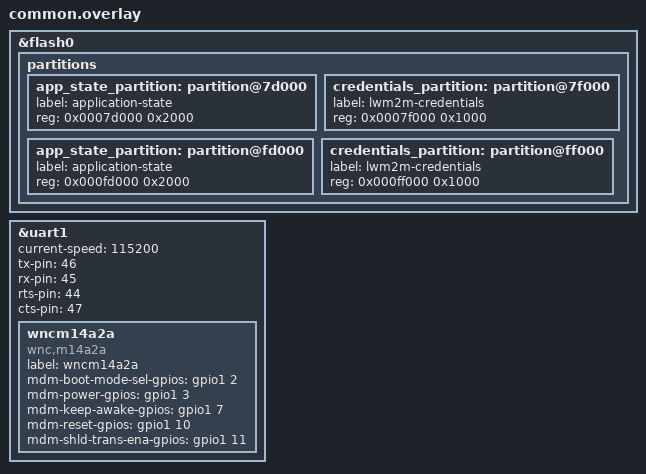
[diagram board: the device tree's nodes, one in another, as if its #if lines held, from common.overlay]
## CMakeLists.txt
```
cmake_minimum_required(VERSION 3.8.2)

# This application has its own Kconfig options.
set(KCONFIG_ROOT ${CMAKE_CURRENT_SOURCE_DIR}/Kconfig)

# CONF_FILE is prj.conf, plus (in addition to, not or) the following, if they
# exist:
#   - local.conf
#   - boards/${BOARD}.conf
#   - boards/${BOARD}-local.conf
#
# The possibly nonexistent files need to be absolute paths; otherwise, the
# behavior of EXISTS is not well-defined.
set(CONF_FILE prj.conf)
if(EXISTS ${CMAKE_CURRENT_SOURCE_DIR}/local.conf)
  set(CONF_FILE ${CONF_FILE} " local.conf")
endif()
if(EXISTS ${CMAKE_CURRENT_SOURCE_DIR}/boards/${BOARD}.conf)
  set(CONF_FILE ${CONF_FILE} " boards/${BOARD}.conf")
endif()
if(EXISTS ${CMAKE_CURRENT_SOURCE_DIR}/boards/${BOARD}-local.conf)
  set(CONF_FILE ${CONF_FILE} " boards/${BOARD}-local.conf")
endif()

if(EXISTS ${CMAKE_CURRENT_SOURCE_DIR}/boards/${BOARD}.overlay)
  # Individual boards must provide DTS overlays which declare the
  # application state partition, and, as appropriate, the DTLS
  # partition.
  set(DTC_OVERLAY_FILE ${DTC_OVERLAY_FILE} " ${CMAKE_CURRENT_SOURCE_DIR}/boards/${BOARD}.overlay")
else()
  # We used to be able to try to go on based on SoC-level defaults,
  # but now that DTS runs before Kconfig, we can't ifdef on the SoC in
  # a DTS overlay anymore. Absent a better solution, fail.
  message(FATAL_ERROR
    "Missing board support for this application; please write
    ${CMAKE_CURRENT_SOURCE_DIR}/boards/${BOARD}.overlay. (This is
    needed for now because DTS now runs before KConfig, so SoC-level
    defaults cannot be applied.)")
endif()

# Mandatory Zephyr boilerplate.
include($ENV{ZEPHYR_BASE}/cmake/app/boilerplate.cmake NO_POLICY_SCOPE)
project(NONE)

# Application "library" build configuration. TODO: move these out of this tree.
target_sources(app PRIVATE src/lib/product_id.c)
target_sources(app PRIVATE src/lib/lwm2m_credentials.c)

# Application build configuration.
target_include_directories(app PRIVATE $ENV{ZEPHYR_BASE}/subsys/testsuite/include/)
target_include_directories(app PRIVATE ${CMAKE_CURRENT_SOURCE_DIR}/src/lib)

target_sources(app PRIVATE src/main.c)
target_sources(app PRIVATE src/app_work_queue.c)
target_sources(app PRIVATE src/lwm2m.c)
target_sources(app PRIVATE src/settings.c)
target_sources(app PRIVATE src/light_control.c)
target_sources_ifdef(CONFIG_NET_L2_BT        app PRIVATE src/bluetooth.c)

target_link_libraries_ifdef(CONFIG_MBEDTLS app PRIVATE mbedTLS)
```

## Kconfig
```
# Copyright (c) 2017 Linaro Limited
# Copyright (c) 2018 Foundries.io
#
# SPDX-License-Identifier: Apache-2.0
#

mainmenu "LWM2M application configuration"

choice
	prompt "FOTA network interface"
	default FOTA_NET_OPENTHREAD if SOC_NRF52840
	default FOTA_NET_BLE6LOWPAN if SOC_NRF52832
	default FOTA_NET_DEFAULT
	help
	  This selection represents an abstract choice for network interface
	  which in turn allows us to set the HW specific configs.

config FOTA_NET_OPENTHREAD
	bool "OpenThread"
	help
	  Connect to host via OpenThread

config FOTA_NET_802154
	bool "IEEE 802.15.4"
	help
	  Connect to host via IEEE 802.15.4

config FOTA_NET_BLE6LOWPAN
	bool "BLE 6LoWPAN"
	help
	  Connect to host via BLE / 6LoWPAN

config FOTA_NET_MODEM
	bool "Modem"
	help
	  Connect to host via modem

config FOTA_NET_DEFAULT
	bool "Other"
	help
	  Connect to host via HW default method (ethernet, etc)

endchoice

config FOTA_DEVICE
	bool "Enable FOTA device settings"
	default y
	select FOTA_DEVICE_SOC_SERIES_KINETIS_K6X if SOC_SERIES_KINETIS_K6X
	select FOTA_DEVICE_SOC_SERIES_NRF52X if SOC_SERIES_NRF52X
	select NET_IPV6 if FOTA_NET_OPENTHREAD || FOTA_NET_BLE6LOWPAN || FOTA_NET_802154
	select NET_CONFIG_NEED_IPV6 if FOTA_NET_OPENTHREAD || FOTA_NET_BLE6LOWPAN || FOTA_NET_802154
	select NET_IPV4 if FOTA_NET_MODEM
	select NET_CONFIG_NEED_IPV4 if FOTA_NET_MODEM
	help
	  Main config to enable device specific settings

config FOTA_ENDPOINT_PREFIX
	string "LwM2M endpoint will start with this string"
	default "zmp"
	help
	  LwM2M endpoint names follow this format "<prefix>:sn:<serial #>".
	  This setting allows you to set the "zmp" portion to a custom value.

config FOTA_DEVICE_SOC_SERIES_KINETIS_K6X
	bool "Kinetis K6x FOTA settings"
	select NET_SHELL
	select NET_IPV4
	select NET_UDP
	select NET_CONFIG_NEED_IPV4
	select NET_DHCPV4 if !FOTA_NET_MODEM
	default n

if FOTA_DEVICE_SOC_SERIES_KINETIS_K6X

# IPv6 is enabled by default in Zephyr's Kconfig when networking is selected.
config NET_IPV6
	default n
config NET_CONFIG_NEED_IPV6
	default n

endif # FOTA_DEVICE_SOC_SERIES_KINETIS_K6X

config FOTA_DEVICE_SOC_SERIES_NRF52X
	bool "Nordic Semiconductor nRF52 FOTA settings"
	select SENSOR
	select TEMP_NRF5
	select ENTROPY_NRF5_RNG
	select NET_SHELL if SOC_NRF52840
	default n

config FOTA_LED_GPIO_INVERTED
	bool "Set this if your hardware has an inverted LED GPIO"
	default y if SOC_NRF52840
	help
	  This setting is used to invert the GPIO pin settings when toggling
	  the "Light Control" LED.

config FOTA_ERASE_PROGRESSIVELY
	bool "Erase flash progressively when updating/receiving new firmware"
	default y if SOC_NRF52840
	help
	 If enabled, flash is erased as necessary when receiving and marking
         new firmware as ok, instead of erasing the whole image slot at once.
         This is necessary on some hardware that has long erase times, to
         prevent long wait times at various stages where large erases are
         performed.

if FOTA_DEVICE_SOC_SERIES_NRF52X

config TEMP_NRF5_NAME
	default "fota-temp"

endif # FOTA_DEVICE_SOC_SERIES_NRF52X

# OpenThread settings
if FOTA_NET_OPENTHREAD
rsource "network_defaults/Kconfig.defaults.ot"
endif # FOTA_NET_OPENTHREAD

# IEEE 802.15.4 Settings
if FOTA_NET_802154
rsource "network_defaults/Kconfig.defaults.ieee802154"
endif # FOTA_NET_802154

# BLE / 6LoWPAN settings
if FOTA_NET_BLE6LOWPAN
rsource "network_defaults/Kconfig.defaults.ble6lowpan"
endif # FOTA_NET_BLE6LOWPAN

# Modem Settings
if FOTA_NET_MODEM
rsource "network_defaults/Kconfig.defaults.modem"
endif # FOTA_NET_MODEM

# General defaults

config NET_RX_STACK_SIZE
	default 5120 if FOTA_NET_OPENTHREAD
	default 2048

config DNS_SERVER1
	default "8.8.8.8" if FOTA_NET_MODEM || FOTA_NET_DEFAULT

module = FOTA
module-dep = LOG
module-str = Log level for FOTA application
source "subsys/logging/Kconfig.template.log_config"

# Leave this at the bottom: we need to override Zephyr's default settings
# with some of the values above.
source "$ZEPHYR_BASE/Kconfig.zephyr"
```

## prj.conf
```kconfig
CONFIG_BOOT_BANNER=y
CONFIG_REBOOT=y
CONFIG_FLASH=y
CONFIG_FLASH_PAGE_LAYOUT=y
CONFIG_NETWORKING=y
CONFIG_GPIO=y

# Network
CONFIG_NET_UDP=y
CONFIG_NET_MGMT=y
CONFIG_NET_MGMT_EVENT=y
CONFIG_NET_PKT_RX_COUNT=10
CONFIG_NET_PKT_TX_COUNT=10
CONFIG_NET_BUF_RX_COUNT=10
CONFIG_NET_BUF_TX_COUNT=10

# FOTA
CONFIG_BOOTLOADER_MCUBOOT=y
CONFIG_FOTA_DEVICE=y
CONFIG_IMG_MANAGER=y
CONFIG_MCUBOOT_IMG_MANAGER=y
# Enable settings storage
CONFIG_SETTINGS=y
CONFIG_FCB=y
CONFIG_SETTINGS_FCB=y

# CONFIG
CONFIG_NET_CONFIG_SETTINGS=y
CONFIG_NET_CONFIG_PEER_IPV6_ADDR="mgmt.foundries.io"
CONFIG_NET_CONFIG_PEER_IPV4_ADDR="mgmt.foundries.io"

# LWM2M
CONFIG_LWM2M=y
CONFIG_LWM2M_SERVER_INSTANCE_COUNT=2
# CONFIG_LWM2M_RW_JSON_SUPPORT is not set
CONFIG_LWM2M_COAP_BLOCK_SIZE=256
CONFIG_LWM2M_IPSO_SUPPORT=y
CONFIG_LWM2M_IPSO_TEMP_SENSOR=y
CONFIG_LWM2M_IPSO_LIGHT_CONTROL=y

# Extra COAP settings
CONFIG_COAP_EXTENDED_OPTIONS_LEN=y
CONFIG_COAP_EXTENDED_OPTIONS_LEN_VALUE=32

# Logging
CONFIG_LOG=y
CONFIG_LOG_DEFAULT_LEVEL=0
CONFIG_BT_LOG_LEVEL_OFF=y
CONFIG_FOTA_LOG_LEVEL_DBG=y
CONFIG_LWM2M_LOG_LEVEL_INF=y

# DNS
CONFIG_DNS_RESOLVER=y
CONFIG_DNS_SERVER_IP_ADDRESSES=y
# Set DNS server entries Kconfig and boards/*.conf
# Needed by socket-based DNS lookup
CONFIG_MINIMAL_LIBC_MALLOC_ARENA_SIZE=360

# Bluetooth (when enabled) debug
#CONFIG_BT_DEBUG_LOG=y
#CONFIG_BT_DEBUG_HCI_DRIVER=y

# Add flash RW to MPU
CONFIG_MPU_ALLOW_FLASH_WRITE=y

# LwM2M workqueue requires a larger stack
CONFIG_SYSTEM_WORKQUEUE_STACK_SIZE=2048

# Debug helpers
#CONFIG_NET_LOG=y
#CONFIG_NET_SOCKETS_LOG_LEVEL_DBG=y
#CONFIG_NET_CORE_LOG_LEVEL_DBG=y
#CONFIG_NET_IF_LOG_LEVEL_DBG=y
#CONFIG_NET_UTILS_LOG_LEVEL_DBG=y
#CONFIG_NET_CONTEXT_LOG_LEVEL_DBG=y
#CONFIG_NET_PKT_LOG_LEVEL_DBG=y
#CONFIG_NET_DEBUG_NET_PKT_ALLOC=y
#CONFIG_NET_BUF_POOL_USAGE=y
#CONFIG_NET_CONN_LOG_LEVEL_DBG=y
#CONFIG_NET_ROUTE_LOG_LEVEL_DBG=y
#CONFIG_NET_IPV4_LOG_LEVEL_DBG=y
#CONFIG_NET_IPV6_LOG_LEVEL_DBG=y
#CONFIG_NET_ICMPV6_LOG_LEVEL_DBG=y
#CONFIG_NET_IPV6_NBR_CACHE_LOG_LEVEL_DBG=y
#CONFIG_NET_6LO_LOG_LEVEL_DBG=y
#CONFIG_NET_UDP_LOG_LEVEL_DBG=y
#CONFIG_NET_L2_ETHERNET_LOG_LEVEL_DBG=y
#CONFIG_NET_L2_BT_LOG_LEVEL_DBG=y
#CONFIG_MODEM_LOG_LEVEL_DBG=y
#CONFIG_INIT_STACKS=y
#CONFIG_STACK_USAGE=y
#CONFIG_STACK_SENTINEL=y
```

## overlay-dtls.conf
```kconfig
CONFIG_LWM2M_DTLS_SUPPORT=y
CONFIG_LWM2M_PEER_PORT=5684

# Special MbedTLS changes
CONFIG_MBEDTLS_HEAP_SIZE=8192
CONFIG_MBEDTLS_SSL_MAX_CONTENT_LEN=1500
CONFIG_MBEDTLS_CIPHER_CCM_ENABLED=y

# Disable RSA, we don't parse certs: saves flash/memory
CONFIG_MBEDTLS_KEY_EXCHANGE_RSA_ENABLED=n
# Enable PSK instead
CONFIG_MBEDTLS_KEY_EXCHANGE_PSK_ENABLED=y

CONFIG_NET_SOCKETS_SOCKOPT_TLS=y
CONFIG_NET_SOCKETS_TLS_MAX_CONTEXTS=4
CONFIG_NET_SOCKETS_ENABLE_DTLS=y

# MbedTLS needs a larger stack
CONFIG_MAIN_STACK_SIZE=2048

# Decrease log level to fit inside flash space
CONFIG_FOTA_LOG_LEVEL_INF=y

# This defaults to y in our configuration, but we aren't relying on
# link layer security and it puts us over our flash budget, so turn it
# back off for now.
# CONFIG_BT_TINYCRYPT_ECC is not set
```

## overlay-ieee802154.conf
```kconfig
# Disable BT configs enabled via board/* conf files
CONFIG_BT=n
CONFIG_BT_CTLR=n
CONFIG_NET_L2_BT=n

# Enable IEEE80215 configs
CONFIG_IEEE802154=y
CONFIG_NET_L2_IEEE802154=y
CONFIG_NET_L2_IEEE802154_SHELL=y
```

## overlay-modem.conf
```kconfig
# Enable WNC-M14A2A LTE-M Modem
CONFIG_MODEM=y
CONFIG_MODEM_SHELL=y
CONFIG_MODEM_WNCM14A2A=y

# extend retry timing to 20 seconds for LTE/LTE-M
CONFIG_COAP_INIT_ACK_TIMEOUT_MS=20000

# Enable modem log
CONFIG_MODEM_LOG_LEVEL_DBG=y
```

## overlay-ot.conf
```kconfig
# Hack: Disable BT on devices which support both for now
CONFIG_BT=n

# Enable OpenThread
CONFIG_NET_L2_OPENTHREAD=y

# Enable C++ for OpenThread stack compilation
CONFIG_CPLUSPLUS=y

# Enable flash page layout extension
CONFIG_FLASH_PAGE_LAYOUT=y

# OpenThread doesn't use NS/NA
CONFIG_NET_IPV6_NBR_CACHE=n
CONFIG_NET_IPV6_MLD=n

# OpenThread requires larger stack sizes
CONFIG_MAIN_STACK_SIZE=2048
CONFIG_SYSTEM_WORKQUEUE_STACK_SIZE=2048
CONFIG_NET_TX_STACK_SIZE=2048

# Use CoAP proxy on gateway
CONFIG_LWM2M_FIRMWARE_UPDATE_PULL_COAP_PROXY_SUPPORT=y
CONFIG_LWM2M_FIRMWARE_UPDATE_PULL_COAP_PROXY_ADDR="coap://[fd11:22::1]:5682"

# Use DNS64 on gateway
CONFIG_DNS_SERVER1="fd11:22::1"

CONFIG_NET_CONFIG_INIT_TIMEOUT=90
```

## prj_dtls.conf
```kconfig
CONFIG_BOOT_BANNER=y
CONFIG_BUILD_TIMESTAMP=y
CONFIG_REBOOT=y
CONFIG_FLASH=y
CONFIG_NETWORKING=y

# Leave device specific settings to enable IPV*
CONFIG_NET_IPV6=n
CONFIG_NET_IPV4=n

# Network
CONFIG_NET_UDP=y
CONFIG_NET_MGMT=y
CONFIG_NET_MGMT_EVENT=y
CONFIG_NET_RX_STACK_SIZE=2048
CONFIG_NET_PKT_RX_COUNT=10
CONFIG_NET_PKT_TX_COUNT=10
CONFIG_NET_BUF_RX_COUNT=10
CONFIG_NET_BUF_TX_COUNT=10

# FOTA
CONFIG_BOOTLOADER_MCUBOOT=y
CONFIG_FOTA_DEVICE=y
CONFIG_IMG_MANAGER=y
CONFIG_MCUBOOT_IMG_MANAGER=y

# NET APP
CONFIG_NET_APP=y
CONFIG_NET_APP_NEED_IPV6=n
CONFIG_NET_APP_NEED_IPV4=n
CONFIG_NET_APP_CLIENT=y
CONFIG_NET_APP_SETTINGS=y
CONFIG_NET_APP_BT_NODE=y
CONFIG_BT_DEVICE_NAME="Linaro IPSP node"
# following BT-related configs which are not needed as a peripheral
CONFIG_BT_CTLR_CONN_PARAM_REQ=n
CONFIG_BT_CTLR_ADV_EXT=n

# COAP
CONFIG_COAP_EXTENDED_OPTIONS_LEN=y
CONFIG_COAP_EXTENDED_OPTIONS_LEN_VALUE=32

# LWM2M
CONFIG_LWM2M=y
CONFIG_LWM2M_RD_CLIENT_INSTANCE_COUNT=1
CONFIG_LWM2M_ENGINE_MAX_OBSERVER=10
CONFIG_LWM2M_SERVER_INSTANCE_COUNT=2
# CONFIG_LWM2M_RW_JSON_SUPPORT is not set
CONFIG_LWM2M_COAP_BLOCK_SIZE=256
CONFIG_LWM2M_FIRMWARE_UPDATE_PULL_COAP_PROXY_SUPPORT=y
CONFIG_LWM2M_IPSO_SUPPORT=y
CONFIG_LWM2M_IPSO_TEMP_SENSOR=y
CONFIG_LWM2M_IPSO_LIGHT_CONTROL=y
CONFIG_SYS_LOG_LWM2M_LEVEL=3

# Logging
CONFIG_SYS_LOG=y
# HACK: temporarily make room on flash
# CONFIG_SYS_LOG_EXT_HOOK is not set
CONFIG_SYS_LOG_FOTA_LEVEL=3

# Bluetooth (when enabled) debug
#CONFIG_BT_DEBUG_LOG=y
#CONFIG_BT_DEBUG_HCI_DRIVER=y

# Add flash RW to MPU
CONFIG_MPU_ALLOW_FLASH_WRITE=y

# DTLS settings
CONFIG_NET_APP_DTLS=y
CONFIG_MBEDTLS=y
CONFIG_MBEDTLS_BUILTIN=y
CONFIG_MBEDTLS_ENABLE_HEAP=y
CONFIG_MBEDTLS_HEAP_SIZE=8192
CONFIG_MBEDTLS_CFG_FILE="config-coap.h"
CONFIG_LWM2M_PEER_PORT=5684

# Debug helpers
#CONFIG_NET_LOG=y
#CONFIG_SYS_LOG_NET_LEVEL=4
#CONFIG_NET_DEBUG_CORE=y
#CONFIG_NET_DEBUG_APP=y
#CONFIG_NET_DEBUG_IF=y
#CONFIG_NET_DEBUG_UTILS=y
#CONFIG_NET_DEBUG_CONTEXT=y
#CONFIG_NET_DEBUG_NET_PKT=y
#CONFIG_NET_DEBUG_NET_PKT_ALL=y
#CONFIG_NET_DEBUG_CONN=y
#CONFIG_NET_DEBUG_ROUTE=y
#CONFIG_NET_DEBUG_IPV4=y
#CONFIG_NET_DEBUG_IPV6=y
#CONFIG_NET_DEBUG_ICMPV6=y
#CONFIG_NET_DEBUG_IPV6_NBR_CACHE=y
#CONFIG_NET_DEBUG_6LO=y
#CONFIG_NET_DEBUG_UDP=y
#CONFIG_NET_DEBUG_L2_ETHERNET=y
#CONFIG_NET_DEBUG_L2_BT=y
#CONFIG_INIT_STACKS=y
#CONFIG_STACK_USAGE=y
```

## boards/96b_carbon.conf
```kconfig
# network stack settings
CONFIG_NET_IF_UNICAST_IPV6_ADDR_COUNT=3
CONFIG_NET_IF_MCAST_IPV6_ADDR_COUNT=2

# bluetooth settings
CONFIG_BLUETOOTH_RX_BUF_COUNT=10
CONFIG_BLUETOOTH_RX_BUF_LEN=128
CONFIG_BLUETOOTH_CONTROLLER_RX_BUFFERS=6
CONFIG_BLUETOOTH_CONTROLLER_TX_BUFFERS=7
CONFIG_BLUETOOTH_RX_STACK_SIZE=2048

# HW settings
CONFIG_TEXT_SECTION_OFFSET=0x100

# temp settings
CONFIG_TEMP_STM32F401X_NAME="fota-mcu-temp"

# Default IP configuration for IPv6 (gateway)
CONFIG_NET_APP_PEER_IPV6_ADDR="fe80::d4e7:0:0:1"

# LWM2M (gateway)
CONFIG_LWM2M_FIRMWARE_UPDATE_PULL_COAP_PROXY_ADDR="fe80::d4e7:0:0:1"
```

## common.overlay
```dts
/*
 * DT overlay file for nodes shared across multiple boards
 * that is *not* shared with the MCUboot build.
 */

#ifdef CONFIG_SOC_NRF52832
&flash0 {
	partitions {
		/* Persistent state the application modifies. */
		app_state_partition: partition@7d000 {
			label = "application-state";
			reg = <0x0007d000 0x2000>;
		};

		/* DTLS credentials etc. */
		credentials_partition: partition@7f000 {
			label = "lwm2m-credentials";
			reg = <0x0007f000 0x1000>;
		};
	};
};
#endif /* CONFIG_SOC_NRF52832 */

#ifdef CONFIG_SOC_NRF52840
&flash0 {
	partitions {
		app_state_partition: partition@fd000 {
			label = "application-state";
			reg = <0x000fd000 0x2000>;
		};

		credentials_partition: partition@ff000 {
			label = "lwm2m-credentials";
			reg = <0x000ff000 0x1000>;
		};
	};
};

&uart1 {
	current-speed = <115200>;
	status = "ok";
	tx-pin = <46>;
	rx-pin = <45>;
	rts-pin = <44>;
	cts-pin = <47>;

	wncm14a2a {
		compatible = "wnc,m14a2a";
		label = "wncm14a2a";
		mdm-boot-mode-sel-gpios = <&gpio1 2 0>;
		mdm-power-gpios = <&gpio1 3 0>;
		mdm-keep-awake-gpios = <&gpio1 7 0>;
		mdm-reset-gpios = <&gpio1 10 0>;
		mdm-shld-trans-ena-gpios = <&gpio1 11 0>;
		status = "ok";
	};
};
#endif /* CONFIG_SOC_NRF52840 */
```

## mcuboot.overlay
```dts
/*
 * DT overlay file for nodes shared across multiple boards
 * that *must be* shared with the MCUboot build.
 */

#ifdef CONFIG_SOC_NRF52832
/*
 * Hard-code the flash partitions for MCUboot on nRF52832.
 *
 * We need more flash for the DTLS use case than some boards provide
 * in the mainline board DTS.
 *
 * This is done unconditionally for all nRF52832 boards for
 * consistency and to make things easier for CI.
 */
&boot_partition {
	reg = <0x00000000 0x8000>;
};
&slot0_partition {
	reg = <0x00008000 0x34000>;
};
&slot1_partition {
	reg = <0x0003c000 0x34000>;
};
&scratch_partition {
	reg = <0x00070000 0xD000>;
};
#endif /* CONFIG_SOC_NRF52832 */
```

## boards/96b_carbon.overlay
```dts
/ {
	chosen {
		zephyr,code-partition = &slot0_partition;
	};
};

&flash0 {
	partitions {
		app_state_partition: partition@c000 {
			label = "application-state";
			reg = <0x0000c000 0x00004000>;
		};
	};
};
```

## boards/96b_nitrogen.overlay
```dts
&flash0 {
	partitions {
		app_state_partition: partition@7d000 {
			label = "application-state";
			reg = <0x0007d000 0x2000>;
		};

		credentials_partition: partition@7f000 {
			label = "lwm2m-credentials";
			reg = <0x0007f000 0x1000>;
		};
	};
};
```

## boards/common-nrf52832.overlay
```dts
&flash0 {
	partitions {
		/*
		 * For most devices we have a storage partition defined,
		 * and here we are shrinking it slightly to make room for
		 * 1 additional partition.  In the case of Nitrogen there
		 * is no storage partition defined.
		 */
		storage_partition: partition@7a000 {
			label = "storage";
			reg = <0x0007a000 0x00005000>;
		};

		/* DTLS credentials etc. */
		credentials_partition: partition@7f000 {
			label = "lwm2m-credentials";
			reg = <0x0007f000 0x1000>;
		};
	};
};
```

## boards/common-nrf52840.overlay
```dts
&flash0 {
	partitions {
		storage_partition: partition@f8000 {
			/* Shrink storage to 0x3000 */
			reg = <0xf8000 0x3000>;
		};

		/* Add a credential partition */
		credentials_partition: partition@fb000 {
			label = "lwm2m-credentials";
			reg = <0xfb000 0x1000>;
		};

		/*
		 * Leave room for OpenThread settings
		 * (last 4 pages of flash: 0xfc000 - 0xfffff)
		 */
	};
};
```

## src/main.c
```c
/*
 * Copyright (c) 2016-2017 Linaro Limited
 * Copyright (c) 2018 Foundries.io
 *
 * SPDX-License-Identifier: Apache-2.0
 */

#define LOG_MODULE_NAME fota_main
#define LOG_LEVEL CONFIG_FOTA_LOG_LEVEL

#include <logging/log.h>
LOG_MODULE_REGISTER(LOG_MODULE_NAME);

#include <zephyr.h>
#include <sensor.h>
#include <gpio.h>
#include <net/lwm2m.h>
#include <tc_util.h>
#include <settings/settings.h>

/* Local helpers and functions */
#include "app_work_queue.h"
#include "product_id.h"
#include "lwm2m.h"
#include "light_control.h"
#include "settings.h"

/* Defines and configs for the IPSO elements */
#define TEMP_DEV		"fota-temp"
#define TEMP_CHAN		SENSOR_CHAN_DIE_TEMP

static struct device *die_dev;
static struct float32_value temp_float;

static int read_temperature(struct device *temp_dev,
			    struct float32_value *float_val)
{
	__unused const char *name = temp_dev->config->name;
	struct sensor_value temp_val;
	int ret;

	ret = sensor_sample_fetch(temp_dev);
	if (ret) {
		LOG_ERR("%s: I/O error: %d", name, ret);
		return ret;
	}

	ret = sensor_channel_get(temp_dev, TEMP_CHAN, &temp_val);
	if (ret) {
		LOG_ERR("%s: can't get data: %d", name, ret);
		return ret;
	}

	LOG_DBG("%s: read %d.%d C", name, temp_val.val1, temp_val.val2);
	float_val->val1 = temp_val.val1;
	float_val->val2 = temp_val.val2;

	return 0;
}

static void *temp_read_cb(u16_t obj_inst_id, size_t *data_len)
{
	/* Only object instance 0 is currently used */
	if (obj_inst_id != 0) {
		*data_len = 0;
		return NULL;
	}

	/*
	 * No need to check if read was successful, just reuse the
	 * previous value which is already stored at temp_float.
	 * This is because there is currently no way to report read_cb
	 * failures to the LWM2M engine.
	 */
	read_temperature(die_dev, &temp_float);
	lwm2m_engine_set_float32("3303/0/5700", &temp_float);
	*data_len = sizeof(temp_float);

	return &temp_float;
}

static int init_temp_device(void)
{
	die_dev = device_get_binding(TEMP_DEV);
	LOG_INF("%s on-die temperature sensor %s",
		die_dev ? "Found" : "Did not find", TEMP_DEV);

	if (!die_dev) {
		LOG_ERR("No temperature device found.");
		return -ENODEV;
	}

	return 0;
}

void main(void)
{
	app_wq_init();

	LOG_INF("Open Source Foundries FOTA LWM2M example application");

	TC_START("Running Built in Self Test (BIST)");

	TC_PRINT("Initializing LWM2M IPSO Temperature Sensor\n");
	if (init_temp_device()) {
		Z_TC_END_RESULT(TC_FAIL, "init_temp_device");
		TC_END_REPORT(TC_FAIL);
		return;
	}
	lwm2m_engine_create_obj_inst("3303/0");
	lwm2m_engine_register_read_callback("3303/0/5700", temp_read_cb);
	lwm2m_engine_set_string("3303/0/5701", "Cel");
	Z_TC_END_RESULT(TC_PASS, "init_temp_device");

	TC_PRINT("Initializing IPSO Light Control\n");
	if (init_light_control()) {
		Z_TC_END_RESULT(TC_FAIL, "init_light_control");
		TC_END_REPORT(TC_FAIL);
		return;
	}
	Z_TC_END_RESULT(TC_PASS, "init_light_control");

	TC_PRINT("Initializing FOTA settings\n");
	if (fota_settings_init()) {
		Z_TC_END_RESULT(TC_FAIL, "fota_settings_init");
		TC_END_REPORT(TC_FAIL);
	}
	Z_TC_END_RESULT(TC_PASS, "fota_settings_init");

	/* Load *all* persistent settings */
	settings_load();

	TC_END_REPORT(TC_PASS);

	if (lwm2m_init(app_work_q)) {
		return;
	}

	/*
	 * From this point on, just handle work.
	 */
	app_wq_run();
}
```

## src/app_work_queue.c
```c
/*
 * Copyright (c) 2016 Intel Corporation
 * Copyright (c) 2016 Wind River Systems, Inc.
 * Copyright (c) 2017 Linaro, Inc.
 *
 * SPDX-License-Identifier: Apache-2.0
 */

/*
 * This file copies the work queue implementation from Zephyr, but
 * allows users to just start running the work queue on a desired
 * thread.
 *
 * This is useful to avoid allocating two thread stacks if one thread
 * (in our case, the main thread) isn't using its stack for the
 * application's lifetime, and could be doing useful work instead.
 *
 * TODO: propose a more upstream-friendly way to support this.
 */

#include "app_work_queue.h"

static struct k_work_q app_queue;

struct k_work_q *app_work_q = &app_queue;

void app_wq_init(void)
{
	k_queue_init(&app_work_q->queue);
}

void app_wq_run(void)
{
	while (1) {
		struct k_work *work;
		k_work_handler_t handler;

		work = k_queue_get(&app_work_q->queue, K_FOREVER);

		handler = work->handler;

		/* Reset pending state so it can be resubmitted by handler */
		if (atomic_test_and_clear_bit(work->flags,
					       K_WORK_STATE_PENDING)) {
			handler(work);
		}

		/* Make sure we don't hog up the CPU if the QUEUE never (or
		 * very rarely) gets empty.
		 */
		k_yield();
	}
}
```

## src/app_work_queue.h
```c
/*
 * Copyright (c) 2017 Linaro Limited
 *
 * SPDX-License-Identifier: Apache-2.0
 */

#ifndef FOTA_APP_WORK_QUEUE_H__
#define FOTA_APP_WORK_QUEUE_H__

/**
 * @file
 * @brief FOTA application work queue
 *
 * This is a single work queue which can be used for sleeping tasks
 * within this application. It is primarily intended to schedule work
 * items which must run sequentially from different application-level
 * threads.
 *
 * Work handlers submitted to this queue may sleep or yield.
 *
 * Work may be submitted to this queue only by threads started from
 * main().
 */

#include <zephyr.h>
#include <zephyr/types.h>

/*
 * This is the work queue itself, which can be passed along to other
 * APIs which submit work.
 */
extern struct k_work_q *app_work_q;

/**
 * @brief Initialize the application work queue.
 *
 * Work may be submitted to the queue after this function returns. It
 * will not be processed until app_wq_run() is called.
 *
 * @see app_wq_run()
 */
void app_wq_init(void);

/**
 * @brief Start handling work queue events in the current thread.
 *
 * Unlike k_work_q_start(), this does not create a new thread;
 * instead, it runs in the caller's.
 *
 * @see k_work_q_start()
 */
FUNC_NORETURN
void app_wq_run(void);

/**
 * @brief Submit work to the application work queue thread.
 * @param work Work to submit
 * @see k_work_submit_to_queue()
 */
static inline void app_wq_submit(struct k_work *work)
{
	k_work_submit_to_queue(app_work_q, work);
}

/**
 * @brief Submit delayed work to the application work queue thread.
 * @param work     Work to submit
 * @param delay_ms Delay in milliseconds
 * @return k_delayed_work_submit_to_queue() return value.
 * @see k_delayed_work_submit_to_queue()
 */
static inline int app_wq_submit_delayed(struct k_delayed_work *work,
					s32_t delay_ms)
{
	return k_delayed_work_submit_to_queue(app_work_q, work, delay_ms);
}

#endif /* FOTA_APP_WORK_QUEUE_H__ */
```

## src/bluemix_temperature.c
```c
/*
 * Copyright (c) 2017 Linaro Limited
 *
 * SPDX-License-Identifier: Apache-2.0
 */

#include "bluemix_temperature.h"

#define SYS_LOG_DOMAIN "bluemix_temp"
#define SYS_LOG_LEVEL CONFIG_SYS_LOG_FOTA_LEVEL
#include <logging/sys_log.h>

#include <errno.h>
#include <stdio.h>

#include <zephyr.h>
#include <device.h>
#include <misc/reboot.h>
#include <sensor.h>
#include <tc_util.h>

#include "bluemix.h"

#include "app_work_queue.h"

#define MAX_FAILURES		5
#define NUM_TEST_RESULTS	5
#define MCU_TEMP_DEV		"fota-mcu-temp"
#define OFFCHIP_TEMP_DEV	"fota-offchip-temp"

struct temp_bluemix_data {
	struct device *mcu_dev;
	struct device *offchip_dev;
	int failures;

	/* For test reporting */
	struct k_work tc_work;
	u8_t tc_results[NUM_TEST_RESULTS];
	u8_t tc_count;
};

static struct temp_bluemix_data temp_bm_data;

static int cb_handle_result(struct temp_bluemix_data *data, int result)
{
	if (result) {
		if (++data->failures >= MAX_FAILURES) {
			SYS_LOG_ERR("Too many Bluemix errors, rebooting!");
			sys_reboot(0);
		}
	} else {
		data->failures = 0;
	}
	/* No reboot was necessary, so keep going. */
	return BLUEMIX_CB_OK;
}

/*
 * This work handler prints the results for publishing temperature
 * readings to Bluemix. It doesn't actually take temperature readings
 * or publish them via the network -- it's only responsible for
 * printing the test results themselves.
 */
static void bluemix_publish_result(struct k_work *work)
{
	struct temp_bluemix_data *data =
		CONTAINER_OF(work, struct temp_bluemix_data, tc_work);
	/*
	 * `result_name' is long enough for the function name, '_',
	 * two digits of test result, and '\0'. If NUM_TEST_RESULTS is
	 * 100 or more, space for more digits is needed.
	 */
	size_t result_len = strlen(__func__) + 1 + 2 + 1;
	char result_name[result_len];
	u8_t result, final_result = TC_PASS;
	size_t i;

	/* Ensure we have enough space to print the result name. */
	BUILD_ASSERT_MSG(NUM_TEST_RESULTS <= 99,
			 "result_len is too small to print test number");

	TC_START("Publish temperature to Bluemix");
	for (i = 0; i < data->tc_count; i++) {
		result = data->tc_results[i];
		snprintf(result_name, sizeof(result_name), "%s_%zu",
			 __func__, i);
		if (result == TC_FAIL) {
			final_result = TC_FAIL;
		}
		_TC_END_RESULT(result, result_name);
	}
	TC_END_REPORT(final_result);
}

static int init_temp_data(struct temp_bluemix_data *data)
{
	data->mcu_dev = device_get_binding(MCU_TEMP_DEV);
	data->offchip_dev = device_get_binding(OFFCHIP_TEMP_DEV);
	data->failures = 0;
	k_work_init(&data->tc_work, bluemix_publish_result);
	data->tc_count = 0;

	SYS_LOG_INF("%s MCU temperature sensor %s",
		    data->mcu_dev ? "Found" : "Did not find",
		    MCU_TEMP_DEV);
	SYS_LOG_INF("%s off-chip temperature sensor %s",
		    data->offchip_dev ? "Found" : "Did not find",
		    OFFCHIP_TEMP_DEV);

	if (!data->mcu_dev && !data->offchip_dev) {
		SYS_LOG_ERR("No temperature devices found.");
		return -ENODEV;
	}

	return 0;
}

static int read_temperature(struct device *temp_dev,
			    struct sensor_value *temp_val)
{
	__unused const char *name = temp_dev->config->name;
	int ret;

	ret = sensor_sample_fetch(temp_dev);
	if (ret) {
		SYS_LOG_ERR("%s: I/O error: %d", name, ret);
		return ret;
	}

	ret = sensor_channel_get(temp_dev, SENSOR_CHAN_TEMP, temp_val);
	if (ret) {
		SYS_LOG_ERR("%s: can't get data: %d", name, ret);
		return ret;
	}

	SYS_LOG_DBG("%s: read %d.%d C",
		    name, temp_val->val1, temp_val->val2);
	return 0;
}

static void handle_test_result(struct temp_bluemix_data *data, u8_t result)
{
	if (data->tc_count >= NUM_TEST_RESULTS) {
		return;
	}

	data->tc_results[data->tc_count++] = result;

	if (data->tc_count == NUM_TEST_RESULTS) {
		app_wq_submit(&data->tc_work);
	}
}

static int temp_bm_conn_fail(struct bluemix_ctx *ctx, void *data)
{
	return cb_handle_result(data, -ENOTCONN);
}

static int temp_bm_poll(struct bluemix_ctx *ctx, void *datav)
{
	struct temp_bluemix_data *data = datav;
	struct sensor_value mcu_val;
	struct sensor_value offchip_val;
	int ret = 0;

	/*
	 * Try to read temperature sensor values, and publish the
	 * whole number portion of temperatures that are read.
	 */
	if (data->mcu_dev) {
		ret = read_temperature(data->mcu_dev, &mcu_val);
	}
	if (ret) {
		goto out;
	}
	if (data->offchip_dev) {
		ret = read_temperature(data->offchip_dev, &offchip_val);
	}
	if (ret) {
		goto out;
	}

	if (data->mcu_dev && data->offchip_dev) {
		ret = bluemix_pub_status_json(ctx,
					      "{"
					      "\"mcutemp\":%d,"
					      "\"temperature\":%d"
					      "}",
					      mcu_val.val1,
					      offchip_val.val1);
	} else if (data->mcu_dev) {
		ret = bluemix_pub_status_json(ctx,
					      "{"
					      "\"mcutemp\":%d"
					      "}",
					      mcu_val.val1);
	} else {
		/* We know we have at least one device. */
		ret = bluemix_pub_status_json(ctx,
					      "{"
					      "\"temperature\":%d"
					      "}",
					      offchip_val.val1);
	}

 out:
	handle_test_result(data, ret ? TC_FAIL : TC_PASS);
	return cb_handle_result(data, ret);
}

static int temp_bm_cb(struct bluemix_ctx *ctx, int event, void *data)
{
	switch (event) {
	case BLUEMIX_EVT_CONN_FAIL:
		return temp_bm_conn_fail(ctx, data);
	case BLUEMIX_EVT_POLL:
		return temp_bm_poll(ctx, data);
	default:
		SYS_LOG_ERR("unexpected callback event %d");
		return BLUEMIX_CB_HALT;
	}
}

int bluemix_temperature_start(void)
{
	int ret;

	ret = init_temp_data(&temp_bm_data);
	if (ret) {
		SYS_LOG_ERR("can't initialize temperature sensors: %d", ret);
		return ret;
	}

	return bluemix_init(temp_bm_cb, &temp_bm_data);
}
```

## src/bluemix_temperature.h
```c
/*
 * Copyright (c) 2017 Linaro Limited
 *
 * SPDX-License-Identifier: Apache-2.0
 */

/**
 * @file
 * @brief Example Bluemix client, which periodically publishes
 *        temperature data to the cloud.
 *
 * Temperature data can come from up to two sources:
 *
 * 1. One on-chip temperature sensor, named "fota-mcu-temp"
 * 2. One off-chip temperature sensor, named "fota-offchip-temp"
 *
 * The target configuration can ensure that a Zephyr temperature
 * sensor device has one of the given names, then configure the
 * Bluemix Kconfig parameters, to use this file. Examples are in the
 * board-level files in boards/.
 */

#ifndef __FOTA_BLUEMIX_TEMPERATURE_H__
#define __FOTA_BLUEMIX_TEMPERATURE_H__

/**
 * @brief Start the background Bluemix thread
 *
 * This thread will periodically attempt to publish temperature data
 * to an IBM Bluemix MQTT broker.
 *
 * @return 0 if the thread is started successfully, and a negative
 *         errno on error.
 */
int bluemix_temperature_start(void);

#endif	/* __FOTA_BLUEMIX_TEMPERATURE_H__ */
```

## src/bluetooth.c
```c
/*
 * Copyright (c) 2016-2017 Linaro Limited
 * Copyright (c) 2018 Foundries.io
 *
 * SPDX-License-Identifier: Apache-2.0
 */

#define LOG_MODULE_NAME fota_bluetooth
#define LOG_LEVEL CONFIG_FOTA_LOG_LEVEL

#include <logging/log.h>
LOG_MODULE_REGISTER(LOG_MODULE_NAME);

#include <zephyr/types.h>
#include <stddef.h>
#include <errno.h>
#include <zephyr.h>
#include <gpio.h>
#include <logging/log_ctrl.h>
#include <misc/reboot.h>
#include <net/bt.h>
#include <net/net_if.h>
#include <net/net_mgmt.h>
#include <init.h>
#include <soc.h>

#include <bluetooth/bluetooth.h>
#include <bluetooth/hci.h>
#include <bluetooth/conn.h>

#include "product_id.h"

static void set_own_bt_addr(bt_addr_le_t *addr)
{
	int i;
	u8_t tmp;

	/*
	 * Generate a static BT addr using the unique product number.
	 */
	for (i = 0; i < 4; i++) {
		tmp = (product_id_get()->number >> i * 8) & 0xff;
		addr->a.val[i] = tmp;
	}

	addr->a.val[4] = 0xe7;
/*
 * For CONFIG_NET_L2_BT_ZEP1656, the U/L bit of the BT MAC is toggled by Zephyr.
 * Later that MAC is used to create the 6LOWPAN IPv6 address.  To account for
 * that, we set 0xd6 here which toggles to 0xd4 later (matching the Linux
 * gateway configuration for bt0).
 */
#if defined(CONFIG_NET_L2_BT_ZEP1656)
	addr->a.val[5] = 0xd6;
#else
	addr->a.val[5] = 0xd4;
#endif
}

/* BT LE Connect/Disconnect callbacks */
static void set_bluetooth_led(bool state)
{
#if defined(BT_GPIO_PIN) && defined(BT_GPIO_CONTROLLER)
	struct device *gpio;

	gpio = device_get_binding(BT_GPIO_CONTROLLER);
	gpio_pin_configure(gpio, BT_GPIO_PIN, GPIO_DIR_OUT);
	gpio_pin_write(gpio, BT_GPIO_PIN, state);
#endif
}

static void connected(struct bt_conn *conn, u8_t err)
{
	if (err) {
		LOG_ERR("BT LE Connection failed: %u", err);
	} else {
		LOG_INF("BT LE Connected");
		set_bluetooth_led(1);
	}
}

static void disconnected(struct bt_conn *conn, u8_t reason)
{
	LOG_ERR("BT LE Disconnected (reason %u), rebooting!", reason);
	set_bluetooth_led(0);
	LOG_PANIC();
	sys_reboot(0);
}

static struct bt_conn_cb conn_callbacks = {
	.connected = connected,
	.disconnected = disconnected,
};

static int bt_network_init(struct device *dev)
{
	bt_addr_le_t bt_addr;
	int ret = 0;

	/* Storage used to provide a BT MAC based on the serial number */
	LOG_INF("Setting Bluetooth MAC");

	memset(&bt_addr, 0, sizeof(bt_addr_le_t));
	bt_addr.type = BT_ADDR_LE_RANDOM;
	set_own_bt_addr(&bt_addr);
	/* MAC is stored in network order, so print reversed */
	LOG_INF("Bluetooth MAC: %02x:%02x:%02x:%02x:%02x:%02x",
		bt_addr.a.val[5], bt_addr.a.val[4], bt_addr.a.val[3],
		bt_addr.a.val[2], bt_addr.a.val[1], bt_addr.a.val[0]);
	ret = bt_set_id_addr(&bt_addr);
	bt_conn_cb_register(&conn_callbacks);

	return ret;
}

int bt_network_disable(void)
{
	/* TODO: use a better way to select BT interface */
	struct net_if *iface = net_if_get_default();
	int ret;

	ret = net_mgmt(NET_REQUEST_BT_DISCONNECT, iface, NULL, 0);
	if (ret < 0) {
		LOG_ERR("Disconnect failed:%d", ret);
		return ret;
	}

	ret = net_mgmt(NET_REQUEST_BT_ADVERTISE, iface, "off", 0);
	if (ret < 0) {
		LOG_ERR("Error stopping advertise:%d", ret);
		return ret;
	}

	return 0;
}

/* last priority in the POST_KERNEL init levels */
SYS_INIT(bt_network_init, APPLICATION, CONFIG_APPLICATION_INIT_PRIORITY);
```

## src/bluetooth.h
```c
/*
 * Copyright (c) 2018 Foundries.io
 *
 * SPDX-License-Identifier: Apache-2.0
 */

#ifndef FOTA_BLUETOOTH_H__
#define FOTA_BLUETOOTH_H__

int bt_network_disable(void);

#endif	/* FOTA_BLUETOOTH_H__ */
```

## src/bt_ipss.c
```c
/*
 * Copyright (c) 2016-2017 Linaro Limited
 *
 * SPDX-License-Identifier: Apache-2.0
 *
 * Based on the ipsp sample available in Zephyr, done by Intel
 *
 */

#include <stddef.h>
#include <errno.h>
#include <misc/byteorder.h>
#include <zephyr.h>

#include <bluetooth/bluetooth.h>
#include <bluetooth/conn.h>
#include <bluetooth/uuid.h>
#include <bluetooth/gatt.h>

#include "bt_ipss.h"

#define DEVICE_NAME "Linaro IPSP node"
#define DEVICE_NAME_LEN (sizeof(DEVICE_NAME) - 1)
#define DEVICE_CONNECTED_NAME "Connected IPSP node"
#define DEVICE_CONNECTED_NAME_LEN (sizeof(DEVICE_CONNECTED_NAME) - 1)
#define UNKNOWN_APPEARANCE 0x0000

static struct bt_gatt_attr attrs[] = {
	/* IP Support Service Declaration */
	BT_GATT_PRIMARY_SERVICE(BT_UUID_IPSS),
};

static struct bt_gatt_service ipss_svc = BT_GATT_SERVICE(attrs);

static const struct bt_data ad[] = {
	BT_DATA_BYTES(BT_DATA_FLAGS, (BT_LE_AD_GENERAL | BT_LE_AD_NO_BREDR)),
	BT_DATA_BYTES(BT_DATA_UUID16_ALL, 0x20, 0x18),
};

static const struct bt_data sd[] = {
	BT_DATA(BT_DATA_NAME_COMPLETE, DEVICE_NAME, DEVICE_NAME_LEN),
};

static const struct bt_data sd_connected[] = {
	BT_DATA(BT_DATA_NAME_COMPLETE, DEVICE_CONNECTED_NAME,
		DEVICE_CONNECTED_NAME_LEN),
};

int ipss_init(struct bt_conn_cb *conn_callbacks)
{
	int ret;

	ret = bt_gatt_service_register(&ipss_svc);
	if (!ret) {
		bt_conn_cb_register(conn_callbacks);
	}

	return ret;
}

/* local copy of set_ad() in subsys/bluetooth/host/hci_core */
static int ipss_set_ad(u16_t hci_op, const struct bt_data *ad, size_t ad_len)
{
	struct bt_hci_cp_le_set_adv_data *set_data;
	struct net_buf *buf;
	int i;

	buf = bt_hci_cmd_create(hci_op, sizeof(*set_data));
	if (!buf) {
		return -ENOBUFS;
	}

	set_data = net_buf_add(buf, sizeof(*set_data));

	memset(set_data, 0, sizeof(*set_data));

	for (i = 0; i < ad_len; i++) {
		/* Check if ad fit in the remaining buffer */
		if (set_data->len + ad[i].data_len + 2 > 31) {
			net_buf_unref(buf);
			return -EINVAL;
		}

		set_data->data[set_data->len++] = ad[i].data_len + 1;
		set_data->data[set_data->len++] = ad[i].type;

		memcpy(&set_data->data[set_data->len], ad[i].data,
		       ad[i].data_len);
		set_data->len += ad[i].data_len;
	}

	return bt_hci_cmd_send_sync(hci_op, buf, NULL);
}

int ipss_set_connected(void)
{
	int err = 0;

	/*
	 * Clearing BT_HCI_OP_LE_SET_SCAN_RSP_DATA is done by calling
	 * set_ad() with NULL data and zero len.
	 */
	err = ipss_set_ad(BT_HCI_OP_LE_SET_SCAN_RSP_DATA, NULL, 0);
	if (!err) {
		err = ipss_set_ad(BT_HCI_OP_LE_SET_SCAN_RSP_DATA,
				  sd_connected, ARRAY_SIZE(sd_connected));
	}

	return err;
}

int ipss_advertise(void)
{
	int err;

	err = bt_le_adv_start(BT_LE_ADV_CONN, ad, ARRAY_SIZE(ad),
			      sd, ARRAY_SIZE(sd));

	return err;
}
```

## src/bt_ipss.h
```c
/*
 * Copyright (c) 2016-2017 Linaro Limited
 *
 * SPDX-License-Identifier: Apache-2.0
 */

#ifndef __FOTA_BT_IPSS_H__
#define __FOTA_BT_IPSS_H__

/* these functions hidden in zephyr/subsys/bluetooth/host/hci_core.h */
extern struct net_buf *bt_hci_cmd_create(u16_t opcode, u8_t param_len);
extern int bt_hci_cmd_send_sync(u16_t opcode, struct net_buf *buf,
				struct net_buf **rsp);

int ipss_init(struct bt_conn_cb *conn_callbacks);
int ipss_set_connected(void);
int ipss_advertise(void);

#endif	/* __FOTA_BT_IPSS_H__ */
```

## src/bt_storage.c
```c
/*
 * Copyright (c) 2016-2017 Linaro Limited
 *
 * SPDX-License-Identifier: Apache-2.0
 */

#define SYS_LOG_DOMAIN "fota/bt_storage"
#define SYS_LOG_LEVEL SYS_LOG_LEVEL_DEBUG
#include <logging/sys_log.h>

#include <zephyr/types.h>
#include <stddef.h>
#include <errno.h>
#include <zephyr.h>

#include <bluetooth/bluetooth.h>
#include <bluetooth/hci.h>
#include <bluetooth/storage.h>

#include <soc.h>

#include "product_id.h"

/* Any by default, can change depending on the hardware implementation */
static bt_addr_le_t bt_addr;

static ssize_t storage_read(const bt_addr_le_t *addr, u16_t key, void *data,
			       size_t length)
{
	if (addr) {
		return -ENOENT;
	}

	if (key == BT_STORAGE_ID_ADDR && length == sizeof(bt_addr)) {
		bt_addr_le_copy(data, &bt_addr);
		return sizeof(bt_addr);
	}

	return -EIO;
}

static ssize_t storage_write(const bt_addr_le_t *addr, u16_t key,
				const void *data, size_t length)
{
	return -ENOSYS;
}

static ssize_t storage_clear(const bt_addr_le_t *addr)
{
	return -ENOSYS;
}

static void set_own_bt_addr(void)
{
	int i;
	u8_t tmp;

	/*
	 * Generate a static BT addr using the unique product number.
	 */
	for (i = 0; i < 4; i++) {
		tmp = (product_id_get()->number >> i * 8) & 0xff;
		bt_addr.a.val[i] = tmp;
	}

	bt_addr.a.val[4] = 0xe7;
	bt_addr.a.val[5] = 0xd6;
}

int bt_storage_init(void)
{
	static const struct bt_storage storage = {
		.read = storage_read,
		.write = storage_write,
		.clear = storage_clear,
	};

	bt_addr.type = BT_ADDR_LE_RANDOM;

	set_own_bt_addr();

	bt_storage_register(&storage);

	SYS_LOG_DBG("Bluetooth storage driver registered");

	return 0;
}
```

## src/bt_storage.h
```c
/*
 * Copyright (c) 2016 Linaro Limited
 *
 * SPDX-License-Identifier: Apache-2.0
 */

#ifndef __FOTA_BT_STORAGE_H__
#define __FOTA_BT_STORAGE_H__

int bt_storage_init(void);

#endif	/* __FOTA_BT_STORAGE_H__ */
```

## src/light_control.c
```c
/*
 * Copyright (c) 2016-2017 Linaro Limited
 * Copyright (c) 2017-2018 Foundries.io
 *
 * SPDX-License-Identifier: Apache-2.0
 */

#define LOG_MODULE_NAME fota_light
#define LOG_LEVEL CONFIG_FOTA_LOG_LEVEL

#include <logging/log.h>
LOG_MODULE_REGISTER(LOG_MODULE_NAME);

#include <zephyr.h>
#include <gpio.h>
#include <net/lwm2m.h>

/* Defines for the IPSO light-control elements */
#define LED_GPIO_PIN		LED0_GPIO_PIN
#define LED_GPIO_FLAGS		LED0_GPIO_FLAGS
#if defined(LED0_GPIO_PORT)
#define LED_GPIO_PORT		LED0_GPIO_PORT
#else
#define LED_GPIO_PORT		LED0_GPIO_CONTROLLER
#endif

static struct device *led_dev;
static u8_t led_current;

/* TODO: Move to a pre write hook that can handle ret codes once available */
static int on_off_cb(u16_t obj_inst_id, u8_t *data, u16_t data_len,
		     bool last_block, size_t total_size)
{
	int ret = 0;
	u8_t led_val;

	if (data_len != 1) {
		LOG_ERR("Length of on_off callback data is incorrect! (%u)",
			data_len);
		return -EINVAL;
	}

	led_val = *data;
	if (led_val != led_current) {
		ret = gpio_pin_write(led_dev, LED_GPIO_PIN,
				     IS_ENABLED(CONFIG_FOTA_LED_GPIO_INVERTED) ?
					!led_val : led_val);
		if (ret) {
			/*
			 * We need an extra hook in LWM2M to better handle
			 * failures before writing the data value and not in
			 * post_write_cb, as there is not much that can be
			 * done here.
			 */
			LOG_ERR("Fail to write to GPIO %d", LED_GPIO_PIN);
			return ret;
		}

		led_current = led_val;
		/* TODO: Move to be set by the IPSO object itself */
		lwm2m_engine_set_s32("3311/0/5852", 0);
	}

	return ret;
}

int init_light_control(void)
{
	int ret;

	led_dev = device_get_binding(LED_GPIO_PORT);
	LOG_INF("%s LED GPIO port %s", led_dev ? "Found" : "Did not find",
		LED_GPIO_PORT);

	if (!led_dev) {
		LOG_ERR("No LED device found.");
		ret = -ENODEV;
		goto fail;
	}

	ret = gpio_pin_configure(led_dev, LED_GPIO_PIN,
				 GPIO_DIR_OUT | LED_GPIO_FLAGS);
	if (ret) {
		LOG_ERR("Error configuring LED GPIO.");
		goto fail;
	}

	ret = gpio_pin_write(led_dev, LED_GPIO_PIN,
			     IS_ENABLED(CONFIG_FOTA_LED_GPIO_INVERTED) ? 1 : 0);
	if (ret) {
		LOG_ERR("Error setting LED GPIO.");
		goto fail;
	}

	ret = lwm2m_engine_create_obj_inst("3311/0");
	if (ret < 0) {
		goto fail;
	}

	ret = lwm2m_engine_register_post_write_callback("3311/0/5850",
							on_off_cb);
	if (ret < 0) {
		goto fail;
	}

	return 0;

fail:
	return ret;
}
```

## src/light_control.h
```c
/*
 * Copyright (c) 2016-2017 Linaro Limited
 * Copyright (c) 2017-2018 Open Source Foundries
 *
 * SPDX-License-Identifier: Apache-2.0
 */

#ifndef FOTA_LIGHT_CONTROL_H__
#define FOTA_LIGHT_CONTROL_H__

int init_light_control(void);

#endif	/* FOTA_LIGHT_CONTROL_H__ */
```
